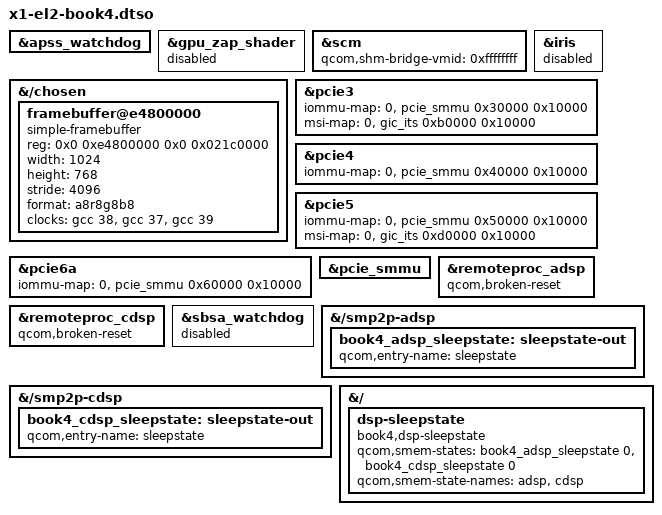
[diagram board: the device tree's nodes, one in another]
// SPDX-License-Identifier: BSD-3-Clause

/*
 * x1 specific modifications required to boot in EL2.
 *
 * Book4 Edge variant (book4-edge-linux): without the ADSP/CDSP iommus,
 * which cause an apps-SMMU fault storm and a hard lockup on X1E laptops.
 * Linux cannot start the DSPs at EL2 by itself; qebspil starts them from
 * UEFI and Linux attaches (qcom,broken-reset, below).
 */

/dts-v1/;
/plugin/;

&apss_watchdog {
	status = "okay";
};

/* We can't and don't need to use zap shader in EL2 as linux can zap the gpu on it's own. */
&gpu_zap_shader {
	status = "disabled";
};

/*
 * SHM bridges owned by Linux itself: without Gunyah there is no HLOS VM to
 * own them, and TrustZone refuses qseecom's buffers (-22: no EFI variables,
 * no RTC). Needs sleep-backport 0027/0028 (qcom_tzmem self-owner, from
 * jglathe's tree via github.com/justririll/x1e-dsp) and
 * CONFIG_QCOM_TZMEM_MODE_SHMBRIDGE. 0xffffffff = QCOM_SCM_VMID_SELF_OWNER
 * (this overlay is built without the preprocessor).
 */
&scm {
	qcom,shm-bridge-vmid = <0xffffffff>;
};

/*
 * The boot framebuffer as the EL2 path leaves it: UEFI's buffer
 * (DisplaySplashBufferInfo / UEFIDisplayInfo: 0xe4800000, 0x21c0000 bytes,
 * natively 2880x1800), but the UEFI Shell that starts this path switches the
 * GOP to 1024x768 (kernel console 128x48 on every EL2 boot; with 2880x1800
 * here the boot text came out as stripes, 23 October). So 1024x768, stride
 * 4096. With the GCC display clocks it needs: this EL2 entry boots without
 * clk_ignore_unused, and the kernel's "Disabling unused clocks" at ~3 s
 * switched them off, so the screen was black until msm took over (~17 s).
 * simpledrm keeps listed clocks on and releases them when msm replaces it;
 * a DT framebuffer also stops sysfb from registering UEFI's a second time.
 * Only GCC clocks: gcc is built in, dispcc is a module loaded later (its
 * clocks are not touched by that cleanup). 38/37/39 = GCC_DISP_HF_AXI_CLK,
 * GCC_DISP_AHB_CLK, GCC_DISP_XO_CLK (no preprocessor here).
 */
&{/chosen} {
	#address-cells = <2>;
	#size-cells = <2>;
	ranges;

	framebuffer@e4800000 {
		compatible = "simple-framebuffer";
		reg = <0x0 0xe4800000 0x0 0x021c0000>;
		width = <1024>;
		height = <768>;
		stride = <4096>;
		format = "a8r8g8b8";
		clocks = <&gcc 38>, <&gcc 37>, <&gcc 39>;
	};
};

&iris {
	/* TODO: Add video-firmware iommus to start IRIS from EL2 */
	status = "disabled";
};

/*
 * When running under Gunyah, this IOMMU is controlled by the firmware,
 * however when we take ownership of it in EL2, we need to configure
 * it properly to use PCIe.
 *
 * Additionally, it seems like ITS emulation in Gunyah is broken so we
 * can't use MSI on some PCIe controllers in EL1. But we can add them
 * here for EL2.
 */
&pcie3 {
	iommu-map = <0 &pcie_smmu 0x30000 0x10000>;
	msi-map = <0 &gic_its 0xb0000 0x10000>;
};

&pcie4 {
	iommu-map = <0 &pcie_smmu 0x40000 0x10000>;
};

&pcie5 {
	iommu-map = <0 &pcie_smmu 0x50000 0x10000>;
	msi-map = <0 &gic_its 0xd0000 0x10000>;
};

&pcie6a {
	iommu-map = <0 &pcie_smmu 0x60000 0x10000>;
};

&pcie_smmu {
	status = "okay";
};

/*
 * The ADSP/CDSP are started before Linux by qebspil (UEFI, see
 * install/el2/): at EL2 Linux can authenticate firmware but not release the
 * reset, so it attaches to the running DSPs (Stephan Gerhold's
 * qcom,broken-reset, as in jglathe's x1-el2.dtso). qebspil starts only the
 * remoteprocs marked like this, so EL1 boots are unaffected.
 */
&remoteproc_adsp {
	qcom,broken-reset;
};

&remoteproc_cdsp {
	qcom,broken-reset;
};

/*
 * The "SBSA watchdog" is implemented in software in Gunyah
 * and can't be used when running in EL2.
 */
&sbsa_watchdog {
	status = "disabled";
};

/*
 * Outbound SMP2P "sleepstate" entries to the ADSP and CDSP, as Windows'
 * qcsubsys8380.sys creates them (FUN_1400a4a80): 0x1000 (bit 12, APSS awake)
 * while running, 0 on Modern Standby entry (\Callback\QcModernStandby, sent by
 * the PEP independently of EnablePowerLimitsInterface). Without the entry the
 * DSPs keep CX up through s2idle. Consumer: book4_dsp_sleepstate
 * (tools/power/sleep-modules). Not EL2-specific; here while it is tested.
 */
&{/smp2p-adsp} {
	book4_adsp_sleepstate: sleepstate-out {
		qcom,entry-name = "sleepstate";
		#qcom,smem-state-cells = <1>;
	};
};

&{/smp2p-cdsp} {
	book4_cdsp_sleepstate: sleepstate-out {
		qcom,entry-name = "sleepstate";
		#qcom,smem-state-cells = <1>;
	};
};

&{/} {
	dsp-sleepstate {
		compatible = "book4,dsp-sleepstate";
		qcom,smem-states = <&book4_adsp_sleepstate 0>, <&book4_cdsp_sleepstate 0>;
		qcom,smem-state-names = "adsp", "cdsp";
	};
};
